# rCSL_syscfg1_001 register map
Vendor: Texas Instruments
Peripheral module from a debugger description file (folder OMAPL138_C6748).
Registers are 32-bit, access not given, reset 0xFFFFFFFF unless marked. A register's access mark holds for its fields unless they carry their own. Offsets are as the file gives them; lines under a group give offsets from that group; [hi:lo] are bit positions; {n}, {i} and the like mark numbered series; 'fields as' and 'values as' point back to an identical list; <NAME> marks a mode.

## SYSCFG1 — System config 1
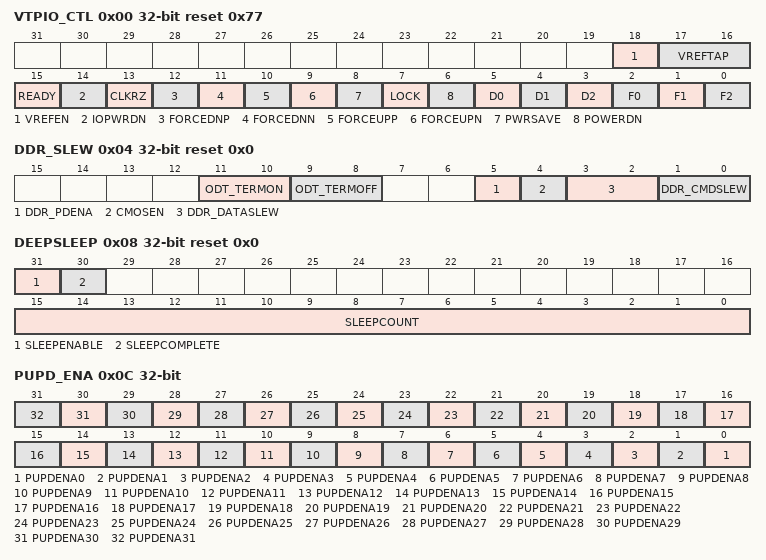
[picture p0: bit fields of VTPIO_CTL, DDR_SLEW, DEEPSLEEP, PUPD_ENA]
0x00 VTPIO_CTL reset 0x77 — VTP controller register
  [18] VREFEN rw — Internal DDR IO Vref Enable
    0=EXTERNAL (Connected to external reference); 1=INTERNAL (Connected to internal reference)
  [17:16] VREFTAP rw — Selection for internal reference voltage level
    0=50_0 (50 percent of VDDS); 1=47.5 percent of VDDS; 2=52.5 percent of VDDS
  [15] READY ro — VTP Ready status
    0=NOT_READY (VTP not ready); 1=READY (VTP ready)
  [14] IOPWRDN rw — Power down control enable for DDR input buffer
    0=DISABLE (Disable power down control); 1=ENABLE (Enable power down control)
  [13] CLKRZ rw — VTP clear
    0=CLEAR (Clear VTP flops)
  [12] FORCEDNP rw — Force decrease PFET drive
  [11] FORCEDNN rw — Force decrease NFET drive
  [10] FORCEUPP rw — Force increase PFET drive
  [9] FORCEUPN rw — Force increase NFET drive
  [8] PWRSAVE rw — VTP power save mode
    0=DISABLE (Disable power save mode); 1=ENABLE (Enable power save mode)
  [7] LOCK rw — VTP impedance lock
    0=UNLOCK (Unlock impedance); 1=LOCK (Lock impedance)
  [6] POWERDN rw — VTP power down
    0=DISABLE (Disable power down); 1=ENABLE (Enable power down)
  [5] D0 rw — Drive strength control bit
  [4] D1 rw — Drive strength control bit
  [3] D2 rw — Drive strength control bit
  [2] F0 rw — Digital filter control bit
  [1] F1 rw — Digital filter control bit
  [0] F2 rw — Digital filter control bit
0x04 DDR_SLEW reset 0x0
  [11:10] ODT_TERMON rw — Controls Thevenin termination mode while IO is in read or write mode
    0=NONE (No termination)
  [9:8] ODT_TERMOFF rw — Controls Thevenin termination mode while IO is not in read or write mode
    0=NONE (No termination)
  [5] DDR_PDENA rw — Enabled pull down for mDDR mode
    0=DISABLE (Disable pull down); 1=ENABLE (Enable pull down)
  [4] CMOSEN rw — Selecte mDDR LVCMOS RX or SSTL18 differential RX
    0=SSTL (SSTL receiver); 1=LVCMOS (LVCMOS receiver)
  [3:2] DDR_DATASLEW ro — Slew rate mode control status for data macro
    0=OFF (Slew rate control off); 1=ON (Slew rate control on)
  [1:0] DDR_CMDSLEW ro — Slew rate mode control status for command macro
    0=OFF (Slew rate control off); 1=ON (Slew rate control on)
0x08 DEEPSLEEP reset 0x0 (reset mask 0xFFFF0000)
  [31] SLEEPENABLE rw — Deep Sleep Enable
    0=NORMAL (Nomarl operating mode); 1=DEEPSLEEP (Start the deep sleep procedure)
  [30] SLEEPCOMPLETE ro — Deep Sleep complete
    0=CONTINUE (Device is still in deep sleep mode); 1=DONE (Device is out of deep sleep mode)
  [15:0] SLEEPCOUNT rw — Deep Sleep Counter
0x0C PUPD_ENA rw — Pullup and Pulldown Enable
  [all] fields
    0=DISABLE; 1=ENABLE
  [n] PUPDENA{n} (n=0..31) — Pullup or Pulldown enable
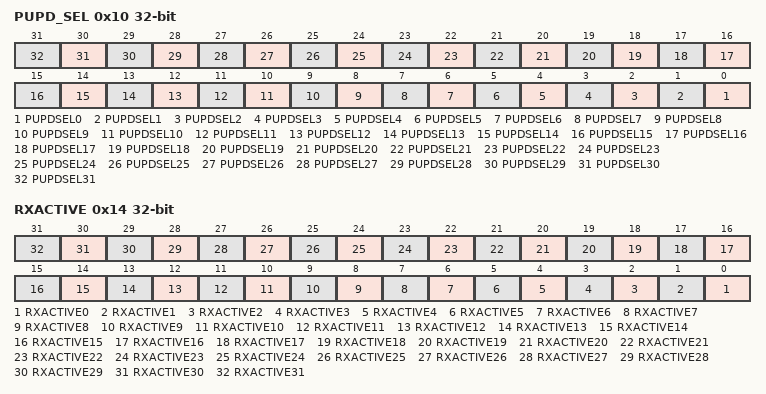
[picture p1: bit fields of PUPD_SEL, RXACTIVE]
0x10 PUPD_SEL rw — Pullup and Pulldown Select
  [all] fields
    0=PULLDOWN (Select pulldown); 1=PULLUP (Select pullup)
  [n] PUPDSEL{n} (n=0..31) — Pullup or Pulldown selection
0x14 RXACTIVE rw — RXACTIVE Control
  [all] fields
    0=DISABLE; 1=ENABLE
  [n] RXACTIVE{n} (n=0..31) — LVCMOS receiver enable
0x18 PWRDN reset 0x3 — Power down
  [0] SATACLK_PWRDN rw — SATA LJCB and RCD Clock Enable
    0=DISABLE; 1=ENABLE
